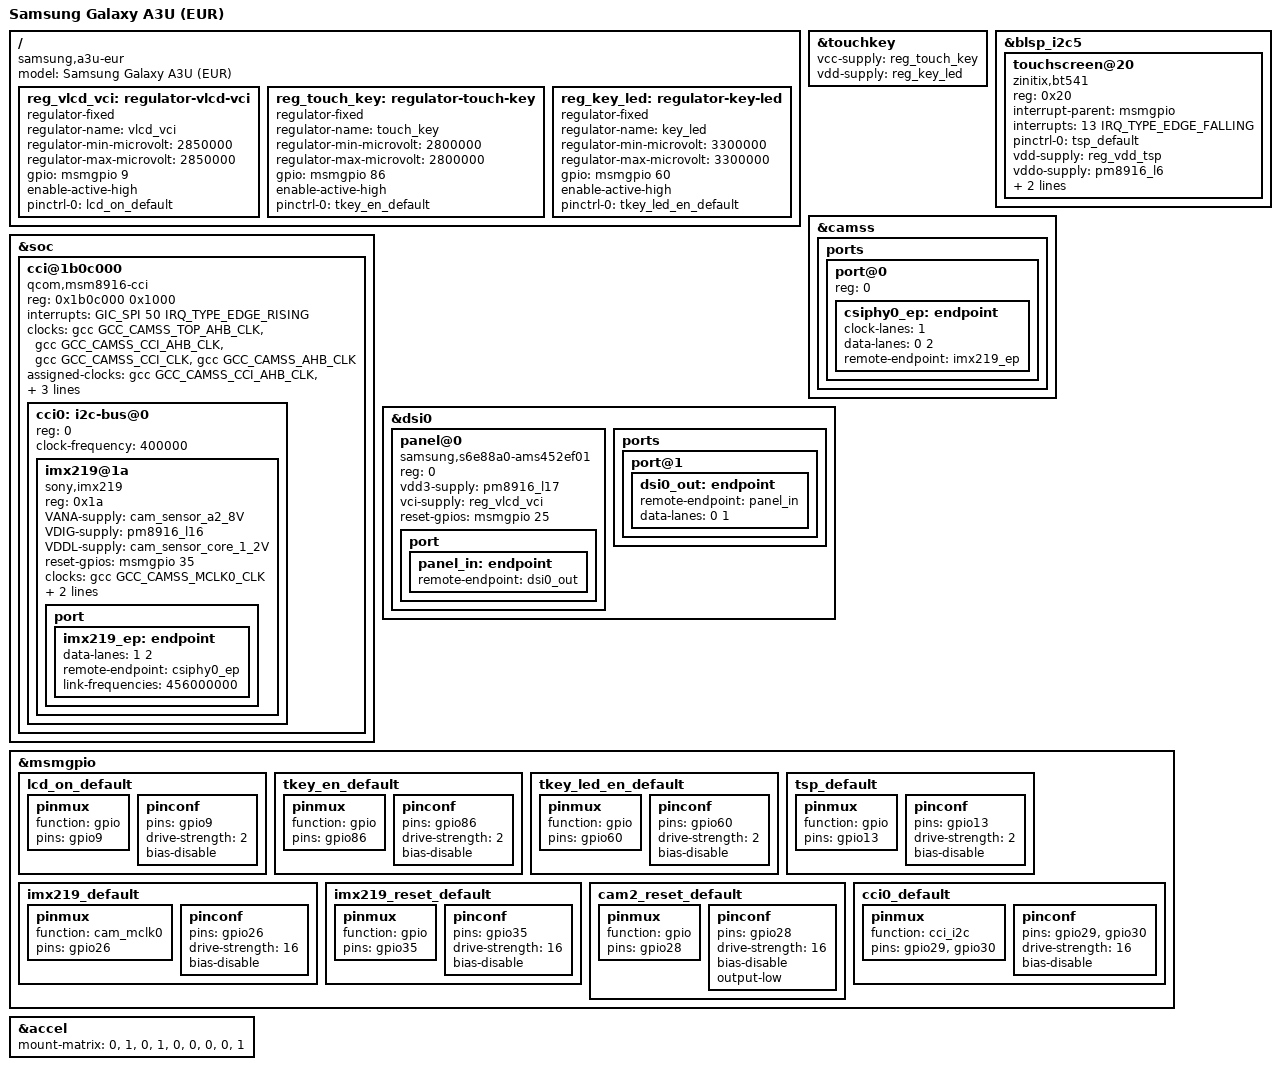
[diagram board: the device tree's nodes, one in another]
// SPDX-License-Identifier: GPL-2.0-only

/dts-v1/;

#include "msm8916-samsung-a2015-common.dtsi"

/ {
	model = "Samsung Galaxy A3U (EUR)";
	compatible = "samsung,a3u-eur", "qcom,msm8916";

	reg_vlcd_vci: regulator-vlcd-vci {
		compatible = "regulator-fixed";
		regulator-name = "vlcd_vci";
		regulator-min-microvolt = <2850000>;
		regulator-max-microvolt = <2850000>;

		gpio = <&msmgpio 9 0>;
		enable-active-high;

		pinctrl-names = "default";
		pinctrl-0 = <&lcd_on_default>;
	};

	reg_touch_key: regulator-touch-key {
		compatible = "regulator-fixed";
		regulator-name = "touch_key";
		regulator-min-microvolt = <2800000>;
		regulator-max-microvolt = <2800000>;

		gpio = <&msmgpio 86 0>;
		enable-active-high;

		pinctrl-names = "default";
		pinctrl-0 = <&tkey_en_default>;
	};

	reg_key_led: regulator-key-led {
		compatible = "regulator-fixed";
		regulator-name = "key_led";
		regulator-min-microvolt = <3300000>;
		regulator-max-microvolt = <3300000>;

		gpio = <&msmgpio 60 0>;
		enable-active-high;

		pinctrl-names = "default";
		pinctrl-0 = <&tkey_led_en_default>;
	};
};

&touchkey {
	vcc-supply = <&reg_touch_key>;
	vdd-supply = <&reg_key_led>;
};

&blsp_i2c5 {
	status = "okay";

	touchscreen@20 {
		compatible = "zinitix,bt541";
		reg = <0x20>;
		interrupt-parent = <&msmgpio>;
		interrupts = <13 IRQ_TYPE_EDGE_FALLING>;
		pinctrl-names = "default";
		pinctrl-0 = <&tsp_default>;
		vdd-supply = <&reg_vdd_tsp>;
		vddo-supply = <&pm8916_l6>;
		touchscreen-size-x = <540>;
		touchscreen-size-y = <960>;
	};
};

&camss {
	status = "okay";

	ports {
		port@0 {
			reg = <0>;
			csiphy0_ep: endpoint {
				clock-lanes = <1>;
				data-lanes = <0 2>;
				remote-endpoint = <&imx219_ep>;
			};
		};
	};
};

&soc {
	
	cci@1b0c000 {
		compatible = "qcom,msm8916-cci";
		#address-cells = <1>;
		#size-cells = <0>;
		reg = <0x1b0c000 0x1000>;
		interrupts = <GIC_SPI 50 IRQ_TYPE_EDGE_RISING>;
		clocks = <&gcc GCC_CAMSS_TOP_AHB_CLK>,
			<&gcc GCC_CAMSS_CCI_AHB_CLK>,
			<&gcc GCC_CAMSS_CCI_CLK>,
			<&gcc GCC_CAMSS_AHB_CLK>;
		clock-names = "camss_top_ahb", "cci_ahb",
			      "cci", "camss_ahb";
		assigned-clocks = <&gcc GCC_CAMSS_CCI_AHB_CLK>,
				  <&gcc GCC_CAMSS_CCI_CLK>;
		assigned-clock-rates = <80000000>, <19200000>;
		pinctrl-names = "default";
		pinctrl-0 = <&cci0_default>;
//		status = "disabled";

		cci0: i2c-bus@0 {
			reg = <0>;
			clock-frequency = <400000>;
			#address-cells = <1>;
			#size-cells = <0>;

			imx219@1a {
				reg = <0x1a>;

				compatible = "sony,imx219";

				VANA-supply = <&cam_sensor_a2_8V>;
				VDIG-supply = <&pm8916_l16>;
				VDDL-supply = <&cam_sensor_core_1_2V>;

				reset-gpios = <&msmgpio 35 GPIO_ACTIVE_HIGH>;

				clocks = <&gcc GCC_CAMSS_MCLK0_CLK>;

				pinctrl-0 = <&imx219_default>, <&imx219_reset_default>, <&cam2_reset_default>;

				port {
					imx219_ep: endpoint {
						data-lanes = <1 2>;
						remote-endpoint = <&csiphy0_ep>;
						link-frequencies = /bits/ 64 <456000000>;
					};
				};
			};
		};
	};
};

&dsi0 {
	panel@0 {
		reg = <0>;

		compatible = "samsung,s6e88a0-ams452ef01";

		vdd3-supply = <&pm8916_l17>;
		vci-supply = <&reg_vlcd_vci>;
		reset-gpios = <&msmgpio 25 GPIO_ACTIVE_HIGH>;

		port {
			panel_in: endpoint {
				remote-endpoint = <&dsi0_out>;
			};
		};
	};

	ports {
		port@1 {
			dsi0_out: endpoint {
				remote-endpoint = <&panel_in>;
				data-lanes = <0 1>;
			};
		};
	};
};

&msmgpio {
	lcd_on_default: lcd_on_default {
		pinmux {
			function = "gpio";
			pins = "gpio9";
		};
		pinconf {
			pins = "gpio9";
			drive-strength = <2>;
			bias-disable;
		};
	};

	tkey_en_default: tkey_en_default {
		pinmux {
			function = "gpio";
			pins = "gpio86";
		};
		pinconf {
			pins = "gpio86";
			drive-strength = <2>;
			bias-disable;
		};
	};

	tkey_led_en_default: tkey_led_en_default {
		pinmux {
			function = "gpio";
			pins = "gpio60";
		};
		pinconf {
			pins = "gpio60";
			drive-strength = <2>;
			bias-disable;
		};
	};

	tsp_default: tsp_default {
		pinmux {
			function = "gpio";
			pins = "gpio13";
		};
		pinconf {
			pins = "gpio13";
			drive-strength = <2>;
			bias-disable;
		};
	};

	imx219_default: imx219_default {
		pinmux {
			function = "cam_mclk0";
			pins = "gpio26";
		};
		pinconf {
			pins = "gpio26";
			drive-strength = <16>;
			bias-disable;
		};
	};

	imx219_reset_default: imx219_reset_default {
		pinmux {
			function = "gpio";
			pins = "gpio35";
		};
		pinconf {
			pins = "gpio35";
			drive-strength = <16>;
			bias-disable;
		};
	};

	cam2_reset_default: cam2_reset_default {
		pinmux {
			function = "gpio";
			pins = "gpio28";
		};
		pinconf {
			pins = "gpio28";
			drive-strength = <16>;
			bias-disable;
			output-low;
		};
	};

	cci0_default: cci0_default {
		pinmux {
			function = "cci_i2c";
			pins = "gpio29", "gpio30";
		};
		pinconf {
			pins = "gpio29", "gpio30";
			drive-strength = <16>;
			bias-disable;
		};
	};
};

&accel {
	mount-matrix = "0", "1", "0",
		       "1", "0", "0",
		       "0", "0", "1";
};
